AUTOSAR XML (schema 00047)
# (C) 2021 HYUNDAI AUTOEVER Corp.
package /KeyM/ClientServerInterfaces
  client server interface KeyMCryptoKey: is-service=true
    operation Update: possible-error=[E_NOT_OK, E_OK, KEYM_E_BUSY, KEYM_E_KEY_CERT_SIZE_MISMATCH, KEYM_E_PARAMETER_MISMATCH]
      6 x arg, all with direction=IN:
        KeyName: type=KeyM_KeyCertNameDataType
        KeyNameLength: type=uint16
        RequestData: type=KeyM_ConstCryptoKeyDataType
        RequestDataLength: type=uint16
        ResponseData: type=KeyM_CryptoKeyDataType
        ResponseDataLength: type=uint16
    8 x error:
      E_NOT_OK: error-code=1
      E_OK: error-code=0
      KEYM_E_BUSY: error-code=2
      KEYM_E_CERT_INVALID: error-code=6
      KEYM_E_KEY_CERT_EMPTY: error-code=10
      KEYM_E_KEY_CERT_SIZE_MISMATCH: error-code=4
      KEYM_E_PARAMETER_MISMATCH: error-code=5
      KEYM_E_PENDING: error-code=3
  client server interface KeyMCryptoKeyNotification: is-service=true
    operation CryptoKeyUpdateCallbackNotification
      arg Result: type=KeyM_ResultType, direction=IN
      arg ResponseDataLength: type=uint16, direction=IN
      arg ResponseData: type=KeyM_CryptoKeyDataType, direction=IN
package /KeyM/DataConstrs
  range KeyM_CertificateStatusType: raw 0x00..0x0B
  range KeyM_ServiceCertificateType: raw 0x01..0x07
  range KeyM_StartType: raw 0x01..0x02
package /KeyM/ImplementationDataTypes
  5 x impl type:
    KeyM_ConstCryptoKeyDataType: category=DATA_REFERENCE, sw-pointer-target-props={target-category=TYPE_REFERENCE, implementation-data-type=uint8, sw-impl-policy=CONST}
    KeyM_CryptoKeyDataType: category=DATA_REFERENCE, sw-pointer-target-props={target-category=TYPE_REFERENCE, implementation-data-type=uint8}
    KeyM_DataPtr: category=DATA_REFERENCE, sw-pointer-target-props={target-category=TYPE_REFERENCE, implementation-data-type=uint8, sw-impl-policy=CONST}
    KeyM_KeyCertNameDataType: category=ARRAY
      element KeyM_KeyCertNameDataType: array-size=255, array-size-semantics=FIXED-SIZE, implementation-data-type=uint8
    KeyM_ResultType: category=VALUE, base-type=uint8, compu {0x05=KEYM_RT_CERT_INVALID_CHAIN_OF_TRUST, 0x02=KEYM_RT_KEY_CERT_INVALID, 0x04=KEYM_RT_KEY_CERT_UPDATE_FAIL, 0x03=KEYM_RT_KEY_CERT_WRITE_FAIL, 0x01=KEYM_RT_NOT_OK, 0x00=KEYM_RT_OK, 0x06=KEYM_RT_PARAMETER_MISMATCH, 0x07=KEYM_RT_KEY_CERT_SIZE_MISMATCH}, range raw 0x00..0x07
package /KeyM/ServiceSwComponentTypes
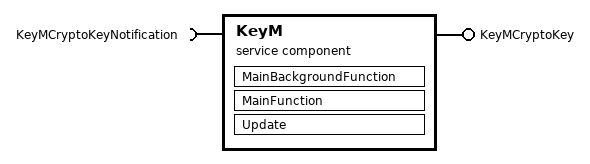
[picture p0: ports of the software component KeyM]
  service sw component type KeyM
    provide port KeyMCryptoKey: server-com-spec{operation=Update, queue-length=1}, provided-interface=KeyMCryptoKey  # Port to execute crypto key related functions.
    require port KeyMCryptoKeyNotification: client-com-spec=CryptoKeyUpdateCallbackNotification, required-interface=KeyMCryptoKeyNotification  # Port to execute crypto key notification related functions.
    behavior KeyMInternalBehavior: handle-termination-and-restart=NO-SUPPORT, included-data-type-set=data-type=KeyM_ResultType
      operation invoked event OperationInvokedEvent_KeyMCryptoKey_Update: start-on-event=Update, operation=KeyMCryptoKey.Update
      runnable MainBackgroundFunction: symbol=KeyM_MainBackgroundFunction
      runnable MainFunction: symbol=KeyM_MainFunction
        sync call SSCP_KeyMCryptoKeyNotification_CryptoKeyUpdateCallbackNotification: operation=KeyMCryptoKeyNotification.CryptoKeyUpdateCallbackNotification
      runnable Update: symbol=KeyM_Update
  swc bsw mapping SwcBswMapping_KeyM: bsw-behavior=BswInternalBehavior_KeyM, swc-behavior=KeyMInternalBehavior
    runnable-mappings:
      bsw-entity=BswCE_KeyM_Update, swc-runnable=Update
      bsw-entity=BswSE_KeyM_MainBackgroundFunction, swc-runnable=MainBackgroundFunction
      bsw-entity=BswSE_KeyM_MainFunction, swc-runnable=MainFunction
  swc implementation SwcImplementation_KeyM: swc-bsw-mapping=SwcBswMapping_KeyM, behavior=KeyMInternalBehavior
